# FM33G0XX register map
File version: 1.0
CPU: SC000 r1p0, little endian, no MPU, no FPU, 3 interrupt priority bits
Registers are 32-bit, read-write, reset 0x0 unless marked. A register's access mark holds for its fields unless they carry their own. Offsets are from the block's base; [hi:lo] are bit positions; {n}, {i} and the like mark numbered series.

## BTIMER1 — BASIC TIMER1 Registers
Base 0x40013000
Same registers: BTIMER2 0x40013044
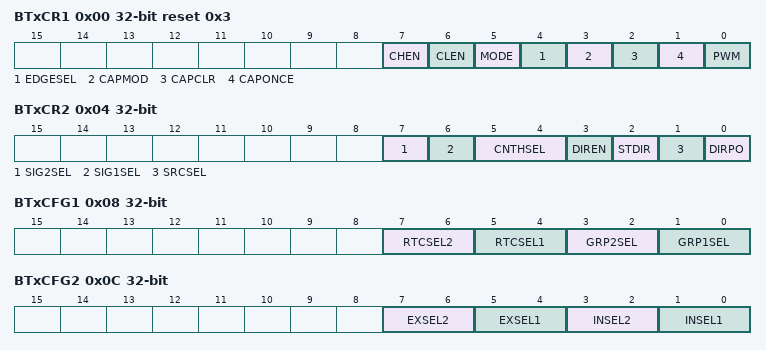
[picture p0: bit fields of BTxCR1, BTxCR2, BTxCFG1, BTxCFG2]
0x00 BTxCR1 reset 0x3 — BTIMER CONTROL REGISTER1
  [7] CHEN
  [6] CLEN
  [5] MODE
    0=8BIT_CNT; 1=16BIT_CAP
  [4] EDGESEL — EDGE SELECT
    0=POS; 1=NEG
  [3] CAPMOD — CAPTURE MODE
    0=PERIOD (PULSE PERIOD); 1=WIDTH (PULSE WIDTH)
  [2] CAPCLR — CLEAR COUNTER AT CAPTURE
    0=NOCLR; 1=CLR
  [1] CAPONCE — CAPTURE ONCE
    0=CONTINUOUS; 1=ONCE
  [0] PWM — PWM MODE OUTPUT ENABLE
0x04 BTxCR2 — BTIMER CONTROL REGISTER 2
  [7] SIG2SEL
    0=CNT_GROUP1; 1=CNT_GROUP2
  [6] SIG1SEL
    0=CAP_GROUP2; 1=CAP_GROUP1
  [5:4] CNTHSEL
    0=ETL; 1=INNERCAP; 2=INNERCNT; 3=ETL
  [3] DIREN
  [2] STDIR
  [1] SRCSEL — SOURCE SELECT
  [0] DIRPO
0x08 BTxCFG1 — BTIMER CONFIG REGISTER 1
  [7:6] RTCSEL2
    0=32768Hz; 1=RTCSec; 2=RTCMin; 3=LPTIM_OUT
  [5:4] RTCSEL1
    0=32768Hz; 1=RTCSec; 2=RTCMin; 3=LPTIM_OUT
  [3:2] GRP2SEL
    0=APBCLK; 1=RTCOUT2; 2=IN_SIG2; 3=EX_SIG2
  [1:0] GRP1SEL
    0=APBCLK; 1=RTCOUT1; 2=IN_SIG1; 3=EX_SIG1
0x0C BTxCFG2 — BTIMER CONFIG REGISTER 2
  [7:6] EXSEL2
    {v}=BT1_IN{v} (v=0..3)
  [5:4] EXSEL1
    {v}=BT1_IN{v} (v=0..3)
  [3:2] INSEL2
    0=UART_RX3; 1=UART_RX4; 2=UART_RX5; 3=RCLP/BT1_OUT
  [1:0] INSEL1
    0=UART_RX0; 1=UART_RX1; 2=UART_RX2; 3=RCLP
0x10 BTxPRES — BTIMER PRESCALE REGISTER
  [7:0] PRESCALE
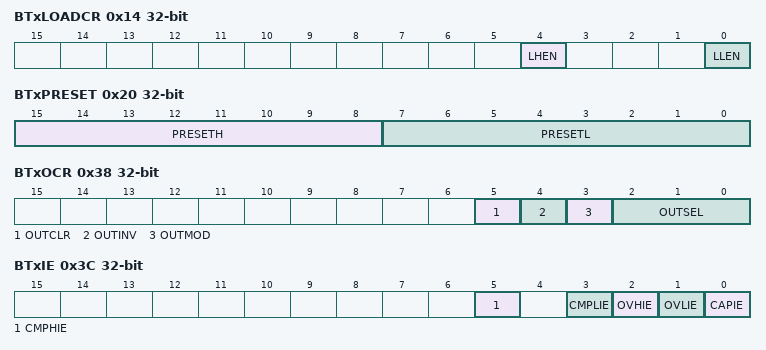
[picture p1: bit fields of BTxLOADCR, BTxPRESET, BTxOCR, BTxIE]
0x14 BTxLOADCR — BTIMER LOADER CONTROL REGISTER
  [4] LHEN — HIGH BYTE LOAD ENABLE
  [0] LLEN — LOW BYTE LOAD ENABLE
0x18 BTxCNTL — BTIMER LOW BYTE COUNTER REGISTER
  [7:0] CNTL
0x1C BTxCNTH — BTIMER HIGH BYTE COUNTER REGISTER
  [7:0] CNTH
0x20 BTxPRESET — BTIMER PRESET REGISTER
  [15:8] PRESETH — PRESETH HIGH BYTE
  [7:0] PRESETL — PRESET LOW BYTE
0x24 BTxLOADL — BTIMER LOW BYTE LOAD REGISTER
  [7:0] LOADL
0x28 BTxLOADH — BTIMER HIGH BYTE LOAD REGISTER
  [7:0] LOADH
0x2C BTxCMPL — BTIME CMPL REGISTER
  [7:0] CMPL
0x30 BTxCMPH — BTIMER CMPH REGISTER
  [7:0] CMPH
0x34 BTxOUTCNT — BTIMER OUTCNT REGISTER
  [11:0] OUTCNT
0x38 BTxOCR — BTIMER OUTPUT CONTROL REGISTER
  [5] OUTCLR
  [4] OUTINV
  [3] OUTMOD
    0=PULSE; 1=REV
  [2:0] OUTSEL
    0=CMPH; 1=CMPL; 2=Group1; 3=Group2; 4=PWM
0x3C BTxIE — BTIMER IE REGISTER
  [5] CMPHIE, [3] CMPLIE, [2] OVHIE, [1] OVLIE, [0] CAPIE
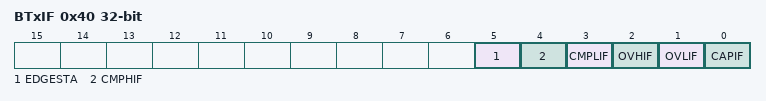
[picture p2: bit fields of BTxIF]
0x40 BTxIF — BTIMER IF REGISTER
  [5] EDGESTA, [4] CMPHIF, [3] CMPLIF, [2] OVHIF, [1] OVLIF, [0] CAPIF

## ETIMER1 — EXTENDED TIMER Registers
Base 0x40013090
Same registers: ETIMER2 0x400130B0, ETIMER3 0x400130D0, ETIMER4 0x400130F0
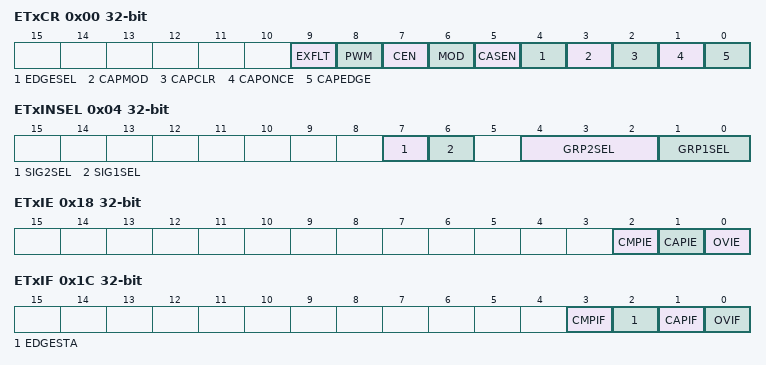
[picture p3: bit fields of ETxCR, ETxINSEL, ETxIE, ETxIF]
0x00 ETxCR — ETIMER CONTROL REGISTER
  [9] EXFLT
  [8] PWM
  [7] CEN
  [6] MOD — MODE
    0=CNT; 1=CAP
  [5] CASEN — Cascade Enable
  [4] EDGESEL — EDGE SELECT
    0=POS; 1=NEG
  [3] CAPMOD — CAPTURE MODE
    0=PERIOD (PULSE PERIOD); 1=WIDTH (PULSE WIDTH)
  [2] CAPCLR — CLEAR COUNTER AT CAPTURE
    0=NOCLR; 1=CLR
  [1] CAPONCE — CAPTURE ONCE
    0=CONTINUOUS; 1=ONCE
  [0] CAPEDGE — CAPTURE EDGE
    0=POS; 1=NEG
0x04 ETxINSEL — ETIMER INPUT SOURCE SELECT REGISTER
  [7] SIG2SEL
    0=Group2; 1=Group1
  [6] SIG1SEL
    0=Group1; 1=Group2
  [4:2] GRP2SEL
    0=UART0_RX/UART2_RX/ET3_IN1/ET4_IN1; 1=UART1_RX/UART3_RX/XTLF/XTLF; 2=XTLF/XTLF/UART4_RX/UART_RX2; 3=ET1_IN1/ET2_IN1/UART5_RX/UART_RX0; 4=ET1_IN2/ET2_IN2/RTCSEC/CMP1O; 5=U7816RX0/U7816RX0/RFU/CMP2O; 6=CMP2O/CMP2O/RFU/RTCSEC; 7=LPTO/LPTO/RFU/LPTO
  [1:0] GRP1SEL
    0=APBCLK; 1=XTLF/XTLF/ET3_IN0/ET4_IN0; 2=RCLP/RCLP/RTCSEC/RTC64HZ; 3=ET1_IN0/ET4_IN0/RCLP/LPTO
0x08 ETxPESCALE1 — ETIMER PESCALE REGISTER 1
  [7:0] PRESCALE1 — PRESCALE for Signal1
0x0C ETxPESCALE2 — ETIMER PESCALE REGISTER 2
  [7:0] PRESCALE2 — PRESCALE FOR Signal2
0x10 ETxIVR — ETIMER INIT VALUE REGISTER
  [15:0] INITVALUE
0x14 ETxCMP — ETIMER CMP REGISTER
  [15:0] CMP
0x18 ETxIE — ETIMER IE REGISTER
  [2] CMPIE, [1] CAPIE, [0] OVIE
0x1C ETxIF — ETIMER IF REGISTER
  [3] CMPIF, [2] EDGESTA, [1] CAPIF, [0] OVIF
